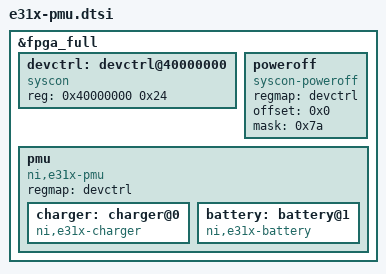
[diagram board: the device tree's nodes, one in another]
/*
 * Copyright (c) 2018 National Instruments Corp
 *
 * SPDX-License-Identifier: GPL-2.0 OR X11
 */

&fpga_full {
	devctrl: devctrl@40000000 {
		compatible = "syscon";
		reg = <0x40000000 0x24>;
	};
	poweroff {
		compatible = "syscon-poweroff";
		regmap = <&devctrl>;
		offset = <0x0>;
		mask = <0x7a>;
	};
	pmu {
		compatible = "ni,e31x-pmu";
		regmap = <&devctrl>;
		status = "okay";
		charger: charger@0{
			compatible = "ni,e31x-charger";
		};
		battery: battery@1{
			compatible = "ni,e31x-battery";
		};
	};
};
